VERSION ""

NS_ :

BS_:

BU_: Panel

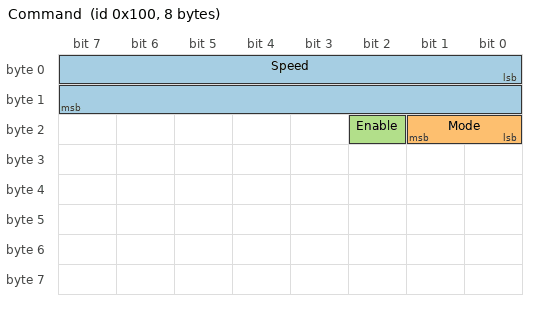
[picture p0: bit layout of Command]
BO_ 256 Command: 8 Panel
 SG_ Speed : 0|16@1+ (1,0) [0|3000] "rpm" Vector__XXX
 SG_ Mode : 16|2@1+ (1,0) [0|2] "" Vector__XXX
 SG_ Enable : 18|1@1+ (1,0) [0|1] "" Vector__XXX

BO_ 2566852609 ExtCommand: 8 Panel
 SG_ Setpoint : 7|16@0+ (0.1,0) [0|1000] "℃" Vector__XXX

BO_ 512 FdData: 64 Panel
 SG_ FdFirst : 0|16@1+ (1,0) [0|65535] "" Vector__XXX
 SG_ FdLast : 504|8@1+ (1,0) [0|255] "" Vector__XXX

CM_ BO_ 256 "Standard frame 0x100: speed, mode and enable, sent every 100 ms by the panel";
CM_ BO_ 2566852609 "Extended frame 0x18FF1001: a Motorola (big-endian) signal";
CM_ BO_ 512 "CAN FD frame 0x200, 64 bytes: needs CAN FD on both ends";
BA_DEF_ BO_ "GenMsgCycleTime" INT 0 65535;
BA_DEF_ BO_ "VFrameFormat" ENUM "StandardCAN","ExtendedCAN","reserved","reserved","reserved","reserved","reserved","reserved","reserved","reserved","reserved","reserved","reserved","reserved","StandardCAN_FD","ExtendedCAN_FD";
BA_DEF_DEF_ "GenMsgCycleTime" 0;
BA_DEF_DEF_ "VFrameFormat" "StandardCAN";
BA_ "GenMsgCycleTime" BO_ 256 100;
BA_ "VFrameFormat" BO_ 2566852609 1;
BA_ "VFrameFormat" BO_ 512 14;
VAL_ 256 Mode 0 "Stop" 1 "Run" 2 "Reverse" ;
VAL_ 256 Enable 0 "Off" 1 "On" ;
